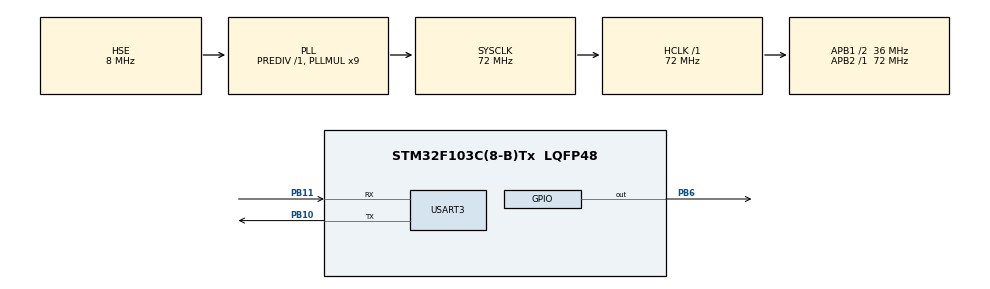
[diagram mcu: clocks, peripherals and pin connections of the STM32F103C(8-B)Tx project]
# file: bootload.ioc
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Mcu.Family=STM32F1
Mcu.Name=STM32F103C(8-B)Tx
Mcu.Package=LQFP48
NVIC.PriorityGroup=NVIC_PRIORITYGROUP_4
NVIC.USART3_IRQn=true\:0\:0\:false\:false\:true\:true\:true
PA13.Mode=Trace_Asynchronous_SW
PA13.Signal=SYS_JTMS-SWDIO
PA14.Mode=Trace_Asynchronous_SW
PA14.Signal=SYS_JTCK-SWCLK
PB10.Mode=Asynchronous
PB10.Signal=USART3_TX
PB11.Mode=Asynchronous
PB11.Signal=USART3_RX
PB3.Mode=Trace_Asynchronous_SW
PB3.Signal=SYS_JTDO-TRACESWO
PB6.Signal=GPIO_Output
PD0-OSC_IN.Mode=HSE-External-Oscillator
PD0-OSC_IN.Signal=RCC_OSC_IN
PD1-OSC_OUT.Mode=HSE-External-Oscillator
PD1-OSC_OUT.Signal=RCC_OSC_OUT
ProjectManager.HeapSize=0x200
ProjectManager.StackSize=0x400
ProjectManager.TargetToolchain=MDK-ARM V5
RCC.AHBFreq_Value=72000000
RCC.APB1CLKDivider=RCC_HCLK_DIV2
RCC.APB1Freq_Value=36000000
RCC.APB1TimFreq_Value=72000000
RCC.APB2Freq_Value=72000000
RCC.APB2TimFreq_Value=72000000
RCC.HCLKFreq_Value=72000000
RCC.PLLMUL=RCC_PLL_MUL9
RCC.PLLSourceVirtual=RCC_PLLSOURCE_HSE
RCC.SYSCLKFreq_VALUE=72000000
RCC.SYSCLKSource=RCC_SYSCLKSOURCE_PLLCLK
RCC.USBFreq_Value=72000000
USART3.VirtualMode=VM_ASYNC
board=custom

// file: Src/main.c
/* USER CODE BEGIN Header */
/**
  ******************************************************************************
  * @file           : main.c
  * @brief          : Main program body
  ******************************************************************************
  * @attention
  *
  * <h2><center>&copy; Copyright (c) 2020 STMicroelectronics.
  * All rights reserved.</center></h2>
  *
  * This software component is licensed by ST under BSD 3-Clause license,
  * the "License"; You may not use this file except in compliance with the
  * License. You may obtain a copy of the License at:
  *                        opensource.org/licenses/BSD-3-Clause
  *
  ******************************************************************************
  */
/* USER CODE END Header */

#include "main.h"
#include "usart.h"
#include "gpio.h"

/* USER CODE BEGIN Includes */
#include "stdio.h"
#include "bootloader.h"
#include "flash.h"
/* USER CODE END Includes */

void SystemClock_Config(void);
/* USER CODE BEGIN PFP */
int fputc(int ch,FILE *f)
{
	HAL_UART_Transmit(&huart3, (uint8_t *)&ch, 1, 0xffff);
	return ch;
}
/* USER CODE END PFP */

int APP1ADDR;//(ADDR_FLASH_BASE + APP1)    // 0x08002000
int APP2ADDR; //(ADDR_FLASH_BASE + APP2)   // 0x08008C00
int UPFLAG=0x0800F800;   //(ADDR_FLASH_BASE + UPFLAG1)   // 0x0800F800
int main(void)
{

  //NVIC_SetVectorTable(NVIC_VectTab_FLASH,0x2000);
  /* MCU Configuration--------------------------------------------------------*/

  /* Reset of all peripherals, Initializes the Flash interface and the Systick. */
  HAL_Init();

  /* Configure the system clock */
  SystemClock_Config();

  /* Initialize all configured peripherals */
  MX_GPIO_Init();
  MX_USART3_UART_Init();

  /* Infinite loop */
  /* USER CODE BEGIN WHILE */

  while (1)
  {
		if(ReadFlashTest(0x08010004)==0x08002000)
		{
			 APP1ADDR=0x08008C00;
	     APP2ADDR=0x08002000;              //重新启动后应用区APP2地址
		 }
		else
		{
			  APP1ADDR=0x08002000;
	      APP2ADDR=0x08008C00;              //重新启动后应用区APP2地址
		}
		if(ReadFlashTest(UPFLAG) == 0x55555555)  //0x55555555
		{
			  Jump2APP(APP2ADDR);                    //采用乒乓式升级，直接跳转地址
		 }
		 else if(ReadFlashTest(UPFLAG) == 0xFFFFFFFF)
		 {
				Jump2APP(APP1ADDR);
		 }
		HAL_Delay(2000);

    /* USER CODE END WHILE */

  }
}

void SystemClock_Config(void)
{
  RCC_OscInitTypeDef RCC_OscInitStruct = {0};
  RCC_ClkInitTypeDef RCC_ClkInitStruct = {0};

  /** Initializes the CPU, AHB and APB busses clocks
  */
  RCC_OscInitStruct.OscillatorType = RCC_OSCILLATORTYPE_HSE;
  RCC_OscInitStruct.HSEState = RCC_HSE_ON;
  RCC_OscInitStruct.HSEPredivValue = RCC_HSE_PREDIV_DIV1;
  RCC_OscInitStruct.HSIState = RCC_HSI_ON;
  RCC_OscInitStruct.PLL.PLLState = RCC_PLL_ON;
  RCC_OscInitStruct.PLL.PLLSource = RCC_PLLSOURCE_HSE;
  RCC_OscInitStruct.PLL.PLLMUL = RCC_PLL_MUL9;
  if (HAL_RCC_OscConfig(&RCC_OscInitStruct) != HAL_OK)
  {
    Error_Handler();
  }
  /** Initializes the CPU, AHB and APB busses clocks
  */
  RCC_ClkInitStruct.ClockType = RCC_CLOCKTYPE_HCLK|RCC_CLOCKTYPE_SYSCLK
                              |RCC_CLOCKTYPE_PCLK1|RCC_CLOCKTYPE_PCLK2;
  RCC_ClkInitStruct.SYSCLKSource = RCC_SYSCLKSOURCE_PLLCLK;
  RCC_ClkInitStruct.AHBCLKDivider = RCC_SYSCLK_DIV1;
  RCC_ClkInitStruct.APB1CLKDivider = RCC_HCLK_DIV2;
  RCC_ClkInitStruct.APB2CLKDivider = RCC_HCLK_DIV1;

  if (HAL_RCC_ClockConfig(&RCC_ClkInitStruct, FLASH_LATENCY_2) != HAL_OK)
  {
    Error_Handler();
  }
}

void Error_Handler(void)
{
}

/************************ (C) COPYRIGHT STMicroelectronics *****END OF FILE****/
